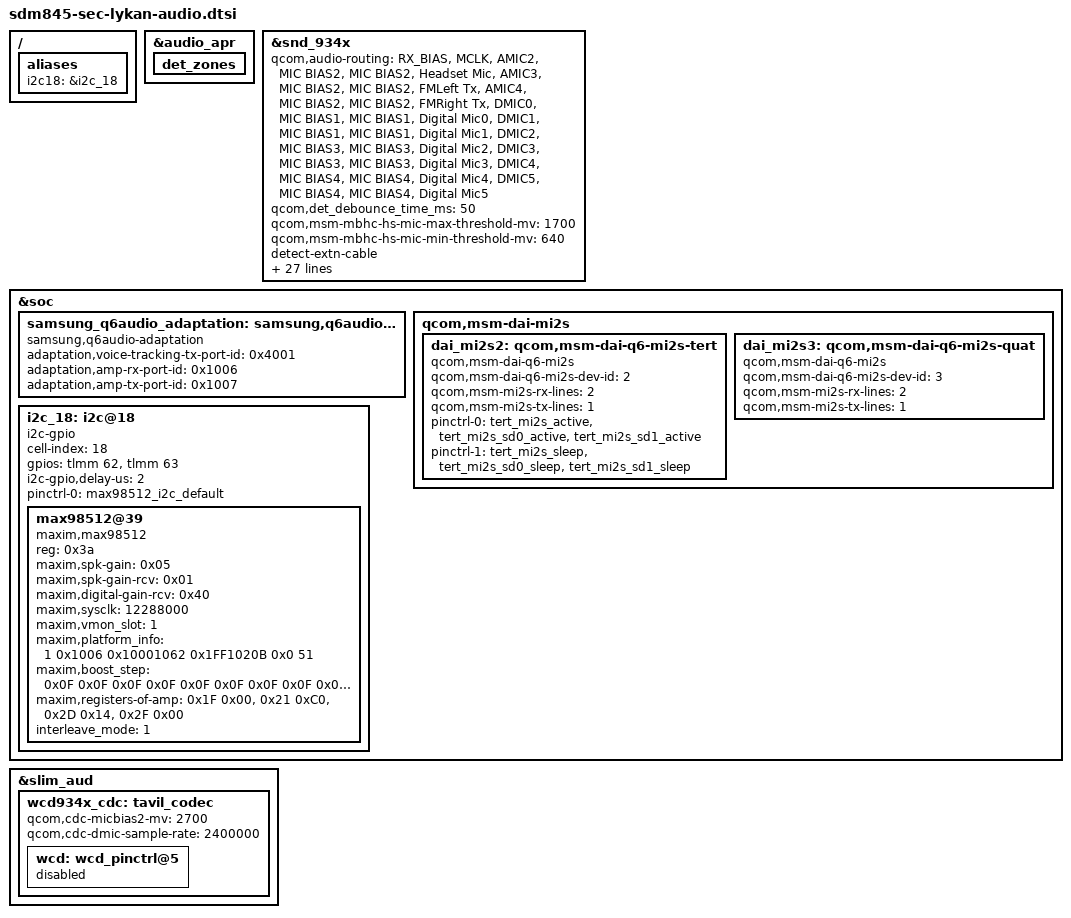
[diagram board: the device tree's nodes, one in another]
/* Copyright (c) 2016-2017, The Linux Foundation. All rights reserved.
 *
 * This program is free software; you can redistribute it and/or modify
 * it under the terms of the GNU General Public License version 2 and
 * only version 2 as published by the Free Software Foundation.
 *
 * This program is distributed in the hope that it will be useful,
 * but WITHOUT ANY WARRANTY; without even the implied warranty of
 * MERCHANTABILITY or FITNESS FOR A PARTICULAR PURPOSE.  See the
 * GNU General Public License for more details.
 */

#include "../qcom/sdm845-audio-overlay.dtsi"

/{
	aliases {
		i2c18 = &i2c_18;
	};
};

&audio_apr {
	det_zones: det_zones {
		#list-det-cells = <2>;
	};
};

&snd_934x {
		/delete-property/qcom,wcn-btfm;
		/delete-property/qcom,auxpcm-audio-intf;
		qcom,audio-routing =
			"RX_BIAS", "MCLK",
			"AMIC2", "MIC BIAS2",
			"MIC BIAS2", "Headset Mic",
			"AMIC3", "MIC BIAS2",
			"MIC BIAS2", "FMLeft Tx",
			"AMIC4", "MIC BIAS2",
			"MIC BIAS2", "FMRight Tx",
			"DMIC0", "MIC BIAS1",
			"MIC BIAS1", "Digital Mic0",
			"DMIC1", "MIC BIAS1",
			"MIC BIAS1", "Digital Mic1",
			"DMIC2", "MIC BIAS3",
			"MIC BIAS3", "Digital Mic2",
			"DMIC3", "MIC BIAS3",
			"MIC BIAS3", "Digital Mic3",
			"DMIC4", "MIC BIAS4",
			"MIC BIAS4", "Digital Mic4",
			"DMIC5", "MIC BIAS4",
			"MIC BIAS4", "Digital Mic5";

	/delete-property/qcom,hph-en0-gpio;
	/delete-property/qcom,hph-en1-gpio;
	/delete-property/qcom,usbc-analog-en1-gpio;
	/delete-property/qcom,usbc-analog-en2-gpio;
	qcom,det_debounce_time_ms = <50>;
	qcom,msm-mbhc-hs-mic-max-threshold-mv = <1700>;
	qcom,msm-mbhc-hs-mic-min-threshold-mv = <640>;
	detect-extn-cable;
	
	asoc-platform = <&pcm0>, <&pcm1>, <&pcm2>, <&voip>, <&voice>,
				<&loopback>, <&compress>, <&hostless>,
				<&afe>, <&lsm>, <&routing>, <&compr>,
				<&pcm_noirq>, <&samsung_q6audio_adaptation>;
	asoc-platform-names = "msm-pcm-dsp.0", "msm-pcm-dsp.1",
				"msm-pcm-dsp.2", "msm-voip-dsp",
				"msm-pcm-voice", "msm-pcm-loopback",
				"msm-compress-dsp", "msm-pcm-hostless",
				"msm-pcm-afe", "msm-lsm-client",
				"msm-pcm-routing", "msm-compr-dsp",
				"msm-pcm-dsp-noirq", "q6audio-adaptation";

	pinctrl-names = "quat-mi2s-active", "quat-mi2s-sleep",
				"quat-tdm-active", "quat-tdm-sleep";
	pinctrl-0 = <&quat_mi2s_active &quat_mi2s_sd0_active
					&quat_mi2s_sd1_active>;
	pinctrl-1 = <&quat_mi2s_sleep &quat_mi2s_sd0_sleep
					&quat_mi2s_sd1_sleep>;
	pinctrl-2 = <&quat_tdm_active &quat_tdm_dout_active>;
	pinctrl-3 = <&quat_tdm_sleep &quat_tdm_dout_sleep>;

	mbhc-button-thres = <&det_zones 13 63>,
				 <&det_zones 88 138>,
				 <&det_zones 138 138>,
				 <&det_zones 225 225>,
				 <&det_zones 450 450>,
				 <&det_zones 620 620>,
				 <&det_zones 620 620>,
				 <&det_zones 620 620>;
	/delete-property/qcom,wsa-max-devs;
	/delete-property/qcom,wsa-devs;
	/delete-property/qcom,wsa-aux-dev-prefix;

	qcom,usbc-ana-en-gpios = <&tlmm 7 0x0>;
	qcom,usbc-ana-sel-gpios = <&tlmm 100 0x0>;
	qcom,msm-mbhc-usbc-jack-v2-supported = <1>;
	qcom,usbc-jack-cont_gpio = <&tlmm 121 0>;
};

&soc {

	/delete-node/msm_cdc_pinctrll;
	/delete-node/msm_cdc_pinctrlr;
	/delete-node/msm_cdc_pinctrl_us_euro_sw;
	/delete-node/msm_cdc_pinctrl_hph_en0;
	/delete-node/msm_cdc_pinctrl_hph_en1;
	/delete-node/swr_master;
	/delete-node/msm_cdc_pinctrl@49;

	samsung_q6audio_adaptation: samsung,q6audio-adaptation {
		compatible = "samsung,q6audio-adaptation";
		adaptation,voice-tracking-tx-port-id = <0x4001>;
		adaptation,amp-rx-port-id = <0x1006>;
		adaptation,amp-tx-port-id = <0x1007>;
	};

	qcom,msm-dai-mi2s {
		dai_mi2s2: qcom,msm-dai-q6-mi2s-tert {
			compatible = "qcom,msm-dai-q6-mi2s";
			qcom,msm-dai-q6-mi2s-dev-id = <2>;
			qcom,msm-mi2s-rx-lines = <2>;
			qcom,msm-mi2s-tx-lines = <1>;
			pinctrl-names = "default", "sleep";
			pinctrl-0 = <&tert_mi2s_active
				     &tert_mi2s_sd0_active
			    	 &tert_mi2s_sd1_active>;
			pinctrl-1 = <&tert_mi2s_sleep
				     &tert_mi2s_sd0_sleep
				     &tert_mi2s_sd1_sleep>;			
		};
		dai_mi2s3: qcom,msm-dai-q6-mi2s-quat {
			compatible = "qcom,msm-dai-q6-mi2s";
			qcom,msm-dai-q6-mi2s-dev-id = <3>;
			qcom,msm-mi2s-rx-lines = <2>;
			qcom,msm-mi2s-tx-lines = <1>;
		};
	};

	i2c_18: i2c@18 {
		cell-index = <18>;
		compatible = "i2c-gpio";
		gpios = <&tlmm 62 0 /* sda */
			&tlmm 63 0 /* scl */
			>;
		i2c-gpio,delay-us = <2>;
		#address-cells = <1>;
		#size-cells = <0>;
		pinctrl-names = "default";
		pinctrl-0 = <&max98512_i2c_default>;

		max98512@39 {
			compatible = "maxim,max98512";
			#sound-dai-cells = <1>;
			reg = <0x3a>;
			maxim,spk-gain= <0x05>;  /* 0x05 15dB */
			maxim,spk-gain-rcv = <0x01>; /* 3dB */
			maxim,digital-gain-rcv = <0x40>; /* -3dB */
			maxim,sysclk = <12288000>;
			maxim,vmon_slot = <1>;
			maxim,platform_info = <1 0x1006 0x10001062 0x1FF1020B 0x0 51>;
			maxim,boost_step = <
				0x0F 0x0F 0x0F 0x0F
				0x0F 0x0F 0x0F 0x0F
				0x0F 0x0F 0x0F 0x0F
				0x0F 0x0F 0x02 0x00
				>;
			maxim,registers-of-amp =
				<0x1F 0x00>,
				<0x21 0xC0>,
				<0x2D 0x14>,
				<0x2F 0x00>;
			interleave_mode = <1>;
		};
	};
};

&slim_aud {
	wcd934x_cdc: tavil_codec {
			qcom,cdc-micbias2-mv = <2700>;
			qcom,cdc-dmic-sample-rate = <2400000>;

			wcd: wcd_pinctrl@5 {
				status = "disabled";
			};
			/*qcom,cdc-dmic-clk-drv-strength = <2>;*/
			/delete-node/msm_cdc_pinctrll;
			/delete-node/msm_cdc_pinctrlr;
			/delete-node/msm_cdc_pinctrl_us_euro_sw;
			/delete-node/msm_cdc_pinctrl_hph_en0;
			/delete-node/msm_cdc_pinctrl_hph_en1;
			/delete-node/swr_master;
	};
};

